# ATSAMD21G18A register map
Vendor: Microchip Technology Inc.; Series: SAMD21; File version: G
CPU: CM0+ r0p1, little endian, no MPU, no FPU, VTOR, 2 interrupt priority bits, 30 interrupts
Registers are 8-bit, read-write, reset 0x0 unless marked. A register's access mark holds for its fields unless they carry their own. Offsets are from the block's base; [hi:lo] are bit positions; {n}, {i} and the like mark numbered series.

## MTB — Cortex-M0+ Micro-Trace Buffer
Base 0x41006000; register names take the prefix MTB_
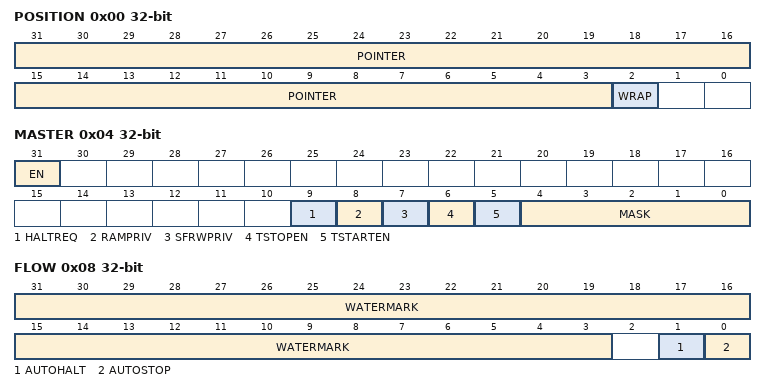
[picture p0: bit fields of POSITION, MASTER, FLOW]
0x00 POSITION 32-bit — MTB Position
  [31:3] POINTER — Trace Packet Location Pointer
  [2] WRAP — Pointer Value Wraps
0x04 MASTER 32-bit — MTB Master
  [31] EN — Main Trace Enable
  [9] HALTREQ — Halt Request
  [8] RAMPRIV — SRAM Privilege
  [7] SFRWPRIV — Special Function Register Write Privilege
  [6] TSTOPEN — Trace Stop Input Enable
  [5] TSTARTEN — Trace Start Input Enable
  [4:0] MASK — Maximum Value of the Trace Buffer in SRAM
0x08 FLOW 32-bit — MTB Flow
  [31:3] WATERMARK — Watermark value
  [1] AUTOHALT — Auto Halt Request
  [0] AUTOSTOP — Auto Stop Tracing
0x0C BASE 32-bit ro — MTB Base
0xF00 ITCTRL 32-bit — MTB Integration Mode Control
0xFA0 CLAIMSET 32-bit — MTB Claim Set
0xFA4 CLAIMCLR 32-bit — MTB Claim Clear
0xFB0 LOCKACCESS 32-bit — MTB Lock Access
0xFB4 LOCKSTATUS 32-bit ro — MTB Lock Status
0xFB8 AUTHSTATUS 32-bit ro — MTB Authentication Status
0xFBC DEVARCH 32-bit ro — MTB Device Architecture
0xFC8 DEVID 32-bit ro — MTB Device Configuration
0xFCC DEVTYPE 32-bit ro — MTB Device Type
{0xFC0+4i} PID{i} 32-bit ro (i=4..7) — CoreSight
{0xFE0+4i} PID{i} 32-bit ro (i=0..3) — CoreSight
{0xFF0+4i} CID{i} 32-bit ro (i=0..3) — CoreSight

## PAC0 — Peripheral Access Controller 0
Base 0x40000000; register names take the prefix PAC_
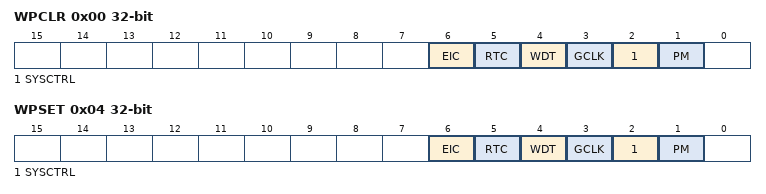
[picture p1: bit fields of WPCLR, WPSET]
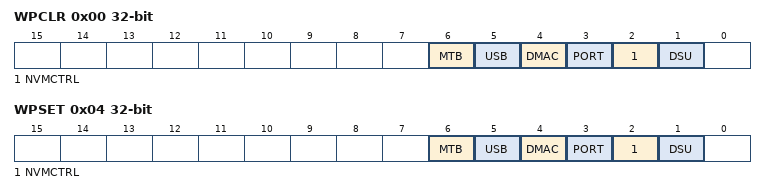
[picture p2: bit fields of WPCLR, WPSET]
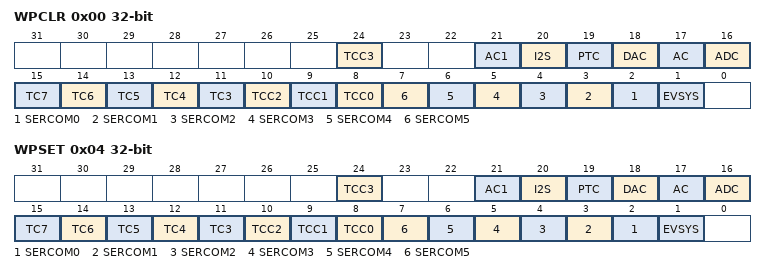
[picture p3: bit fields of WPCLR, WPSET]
0x00 WPCLR 32-bit — Write Protection Clear
  [6] EIC write-1-sets — EIC Write Protection Clear
  [5] RTC write-1-sets — RTC Write Protection Clear
  [4] WDT write-1-sets — WDT Write Protection Clear
  [3] GCLK write-1-sets — GCLK Write Protection Clear
  [2] SYSCTRL write-1-sets — SYSCTRL Write Protection Clear
  [1] PM write-1-sets — PM Write Protection Clear
0x04 WPSET 32-bit — Write Protection Set
  [6] EIC write-1-sets — EIC Write Protection Set
  [5] RTC write-1-sets — RTC Write Protection Set
  [4] WDT write-1-sets — WDT Write Protection Set
  [3] GCLK write-1-sets — GCLK Write Protection Set
  [2] SYSCTRL write-1-sets — SYSCTRL Write Protection Set
  [1] PM write-1-sets — PM Write Protection Set

## PAC1 — Peripheral Access Controller 1
Base 0x41000000; register names take the prefix PAC_
0x00 WPCLR 32-bit — Write Protection Clear
  [6] MTB write-1-sets — MTB Write Protection Clear
  [5] USB write-1-sets — USB Write Protection Clear
  [4] DMAC write-1-sets — DMAC Write Protection Clear
  [3] PORT write-1-sets — PORT Write Protection Clear
  [2] NVMCTRL write-1-sets — NVMCTRL Write Protection Clear
  [1] DSU write-1-sets — DSU Write Protection Clear
0x04 WPSET 32-bit — Write Protection Set
  [6] MTB write-1-sets — MTB Write Protection Set
  [5] USB write-1-sets — USB Write Protection Set
  [4] DMAC write-1-sets — DMAC Write Protection Set
  [3] PORT write-1-sets — PORT Write Protection Set
  [2] NVMCTRL write-1-sets — NVMCTRL Write Protection Set
  [1] DSU write-1-sets — DSU Write Protection Set

## PAC2 — Peripheral Access Controller 2
Base 0x42000000; register names take the prefix PAC_
0x00 WPCLR 32-bit — Write Protection Clear
  [24] TCC3 write-1-sets — TCC3 Write Protection Clear
  [21] AC1 write-1-sets — AC1 Write Protection Clear
  [20] I2S write-1-sets — I2S Write Protection Clear
  [19] PTC write-1-sets — PTC Write Protection Clear
  [18] DAC write-1-sets — DAC Write Protection Clear
  [17] AC write-1-sets — AC Write Protection Clear
  [16] ADC write-1-sets — ADC Write Protection Clear
  [n+8] TC{n} write-1-sets (n=3..7) — TC{n} Write Protection Clear
  [10] TCC2 write-1-sets — TCC2 Write Protection Clear
  [9] TCC1 write-1-sets — TCC1 Write Protection Clear
  [8] TCC0 write-1-sets — TCC0 Write Protection Clear
  [n+2] SERCOM{n} write-1-sets (n=0..5) — SERCOM{n} Write Protection Clear
  [1] EVSYS write-1-sets — EVSYS Write Protection Clear
0x04 WPSET 32-bit — Write Protection Set
  [24] TCC3 write-1-sets — TCC3 Write Protection Set
  [21] AC1 write-1-sets — AC1 Write Protection Set
  [20] I2S write-1-sets — I2S Write Protection Set
  [19] PTC write-1-sets — PTC Write Protection Set
  [18] DAC write-1-sets — DAC Write Protection Set
  [17] AC write-1-sets — AC Write Protection Set
  [16] ADC write-1-sets — ADC Write Protection Set
  [n+8] TC{n} write-1-sets (n=3..7) — TC{n} Write Protection Set
  [10] TCC2 write-1-sets — TCC2 Write Protection Set
  [9] TCC1 write-1-sets — TCC1 Write Protection Set
  [8] TCC0 write-1-sets — TCC0 Write Protection Set
  [n+2] SERCOM{n} write-1-sets (n=0..5) — SERCOM{n} Write Protection Set
  [1] EVSYS write-1-sets — EVSYS Write Protection Set
